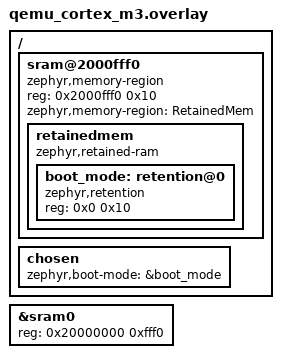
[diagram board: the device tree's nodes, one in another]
/*
 * Copyright (c) 2026 Dhruv Menon <dhruvmenon1104@gmail.com>
 *
 * SPDX-License-Identifier: Apache-2.0
 */

/ {
	sram@2000fff0 {
		compatible = "zephyr,memory-region", "mmio-sram";
		reg = <0x2000fff0 0x10>;
		ranges = <0x0 0x2000fff0 0x10>;
		zephyr,memory-region = "RetainedMem";
		status = "okay";
		#address-cells = <1>;
		#size-cells = <1>;

		retainedmem {
			compatible = "zephyr,retained-ram";
			status = "okay";
			#address-cells = <1>;
			#size-cells = <1>;
			ranges;

			boot_mode: retention@0 {
				compatible = "zephyr,retention";
				status = "okay";
				reg = <0x0 0x10>;
			};
		};
	};

	chosen {
		zephyr,boot-mode = &boot_mode;
	};
};

&sram0 {
	reg = <0x20000000 0xfff0>;
};
